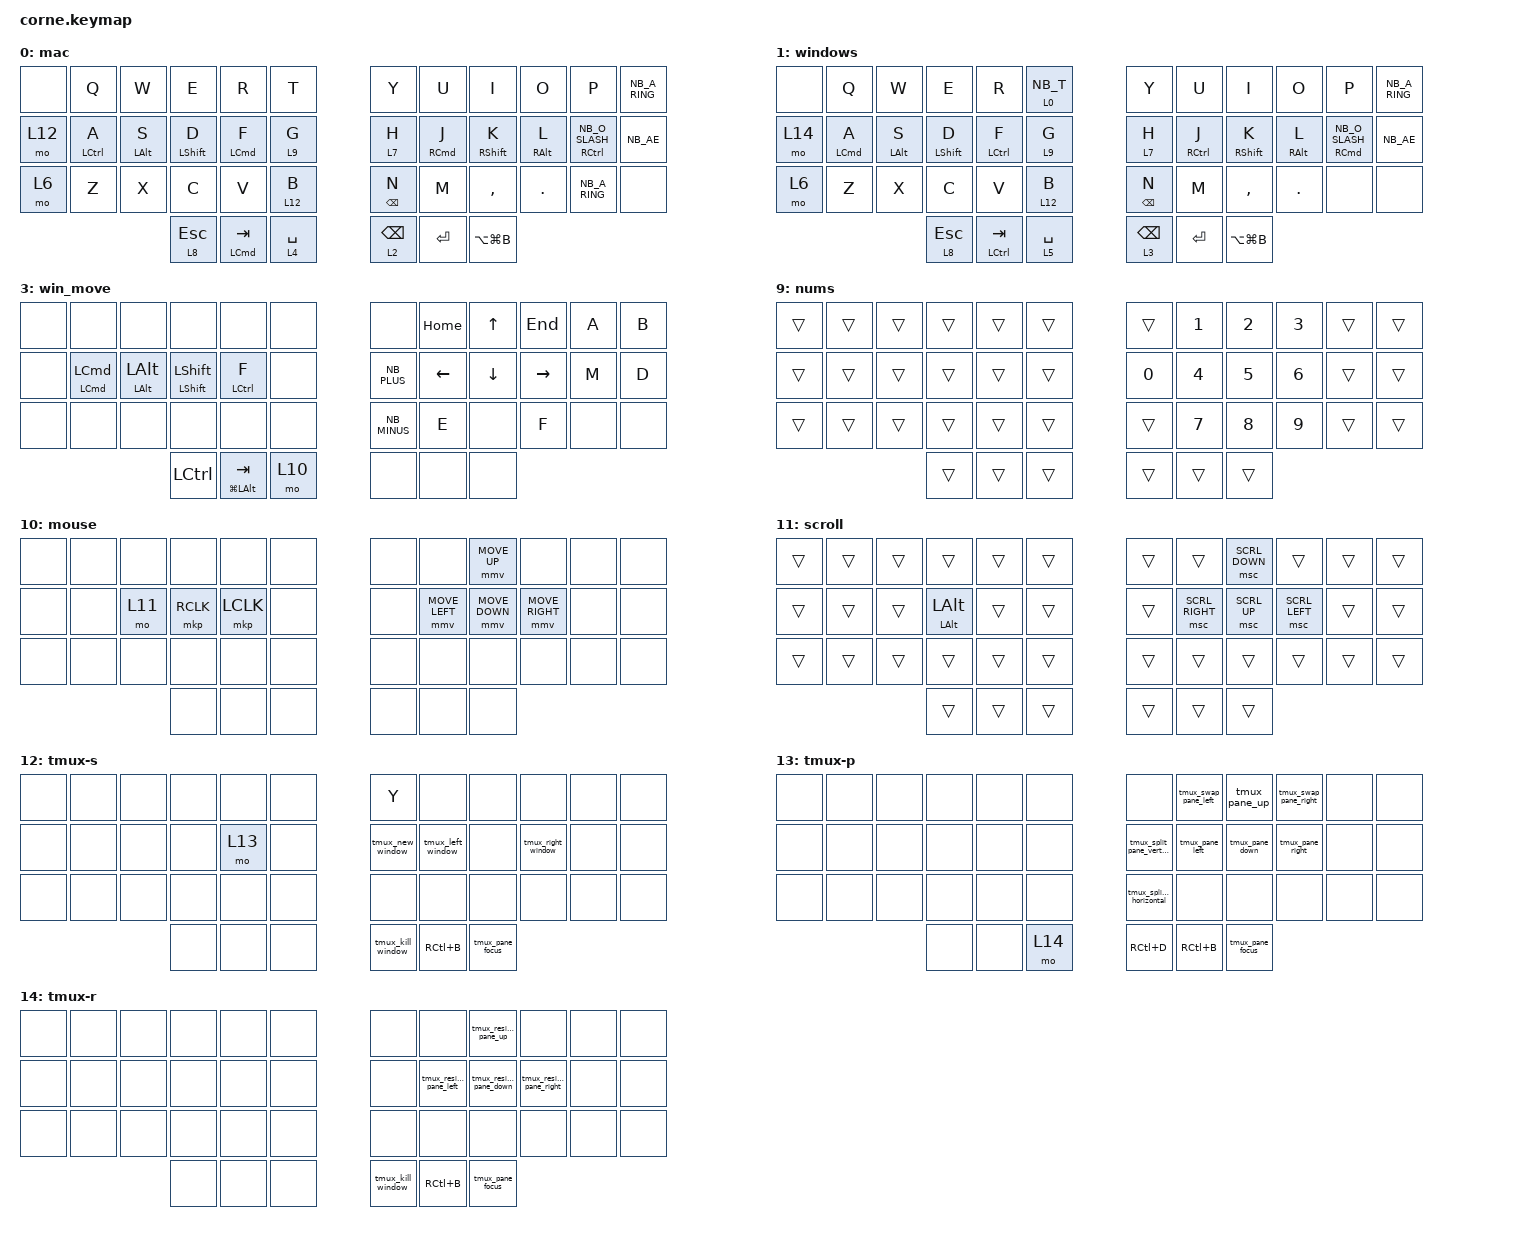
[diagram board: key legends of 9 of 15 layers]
/*
 * Copyright (c) 2020 The ZMK Contributors
 *
 * SPDX-License-Identifier: MIT
 */

#include "keys_nb.h"
#include <behaviors.dtsi>
#include <dt-bindings/zmk/bt.h>
#include <dt-bindings/zmk/keys.h>
#include <dt-bindings/zmk/pointing.h>

#define ZMK_POINTING_DEFAULT_MOVE_VAL 900

/ {
    behaviors {
        mt: mod_tap {
            compatible = "zmk,behavior-hold-tap";
            #binding-cells = <2>;
            flavor = "tap-preferred";
            tapping-term-ms = <180>;
            require-prior-idle-ms = <150>;
            bindings = <&kp>, <&kp>;

            #binding-cells = <2>;
            hold-trigger-on-release;
        };

        os_mac: os_mac {
            compatible = "zmk,behavior-macro";
            label = "OS_MAC";
            #binding-cells = <0>;

            // Select BLE profile 0 and set base layer to Mac (layer 0)

            bindings = <&bt BT_SEL 0 &to 0>;
        };

        os_win: os_win {
            compatible = "zmk,behavior-macro";
            label = "OS_WIN";
            #binding-cells = <0>;

            // Select BLE profile 1 and set base layer to Windows (layer 1)

            bindings = <&bt BT_SEL 1 &to 1>;
        };
    };

    macros {
        tmux_new_window: tmux_new_window {
            compatible = "zmk,behavior-macro";
            #binding-cells = <0>;
            bindings = <&kp RC(B) &kp C>;
            label = "TMUX_NEW_WINDOW";
        };

        tmux_window_1: tmux_window_1 {
            compatible = "zmk,behavior-macro";
            #binding-cells = <0>;
            bindings = <&kp RC(B) &kp N0>;
            label = "TMUX_WINDOW_1";
        };

        tmux_window_2: tmux_window_2 {
            compatible = "zmk,behavior-macro";
            #binding-cells = <0>;
            bindings = <&kp RC(B) &kp N1>;
            label = "TMUX_WINDOW_2";
        };

        tmux_window_3: tmux_window_3 {
            compatible = "zmk,behavior-macro";
            #binding-cells = <0>;
            bindings = <&kp RC(B) &kp NUMBER_2>;
            label = "TMUX_WINDOW_3";
        };

        tmux_window_4: tmux_window_4 {
            compatible = "zmk,behavior-macro";
            #binding-cells = <0>;
            bindings = <&kp RC(B) &kp NUMBER_3>;
            label = "TMUX_WINDOW_4";
        };

        tmux_kill_window: tmux_kill_window {
            compatible = "zmk,behavior-macro";
            #binding-cells = <0>;
            bindings = <&kp RC(B) &kp NB_AMPERSAND>;
            label = "TMUX_KILL_WINDOW";
        };

        tmux_right_window: tmux_right_arrow {
            compatible = "zmk,behavior-macro";
            #binding-cells = <0>;
            bindings = <&kp RC(B) &kp N>;
            label = "TMUX_RIGHT_ARROW";
        };

        tmux_left_window: tmux_left_arrow {
            compatible = "zmk,behavior-macro";
            #binding-cells = <0>;
            bindings = <&kp RC(B) &kp P>;
            label = "TMUX_LEFT_ARROW";
        };

        tmux_split_pane_horizontal: tmux_split_pane_up {
            compatible = "zmk,behavior-macro";
            #binding-cells = <0>;
            bindings = <&kp RC(B) &kp NB_DOUBLE_QUOTES>;
            label = "TMUX_SPLIT_PANE_UP";
        };

        tmux_split_pane_vertical: tmux_split_pane_down {
            compatible = "zmk,behavior-macro";
            #binding-cells = <0>;
            bindings = <&kp RC(B) &kp NB_PERCENT>;
            label = "TMUX_SPLIT_PANE_DOWN";
        };

        tmux_pane_up: tmux_pane_up {
            compatible = "zmk,behavior-macro";
            #binding-cells = <0>;
            bindings = <&kp RC(B) &kp UP_ARROW>;
            label = "TMUX_PANE_UP";
        };

        tmux_pane_down: tmux_pane_down {
            compatible = "zmk,behavior-macro";
            #binding-cells = <0>;
            bindings = <&kp RC(B) &kp DOWN_ARROW>;
            label = "TMUX_PANE_DOWN";
        };

        tmux_pane_left: tmux_pane_left {
            compatible = "zmk,behavior-macro";
            #binding-cells = <0>;
            bindings = <&kp RC(B) &kp LEFT_ARROW>;
            label = "TMUX_PANE_LEFT";
        };

        tmux_pane_right: tmux_pane_right {
            compatible = "zmk,behavior-macro";
            #binding-cells = <0>;
            bindings = <&kp RC(B) &kp RIGHT_ARROW>;
            label = "TMUX_PANE_RIGHT";
        };

        tmux_swap_pane_left: tmux_swap_pane_left {
            compatible = "zmk,behavior-macro";
            #binding-cells = <0>;
            bindings = <&kp RC(B) &kp LA(LS(N8))>;
            label = "TMUX_SWAP_PANE_LEFT";
        };

        tmux_swap_pane_right: tmux_swap_pane_right {
            compatible = "zmk,behavior-macro";
            #binding-cells = <0>;
            bindings = <&kp RC(B) &kp LA(LS(N9))>;
            label = "TMUX_SWAP_PANE_RIGHT";
        };

        tmux_pane_focus: tmux_pane_focus {
            compatible = "zmk,behavior-macro";
            #binding-cells = <0>;
            bindings = <&kp RC(B)>, <&macro_wait_time 50>, <&kp Z>;

            label = "TMUX_PANE_FOCUS";
        };

        tmux_resize_pane_up: tmux_resize_pane_up {
            compatible = "zmk,behavior-macro";
            #binding-cells = <0>;
            bindings =
                <&kp RC(B)>,
                <&macro_wait_time 50>,
                <&mt RC(PAGE_UP) RC(PAGE_UP)>;

            label = "TMUX_RESIZE_PANE_UP";
        };

        tmux_resize_pane_down: tmux_resize_pane_down {
            compatible = "zmk,behavior-macro";
            #binding-cells = <0>;
            bindings =
                <&kp RC(B)>,
                <&macro_wait_time 50>,
                <&mt RC(PAGE_DOWN) RC(PAGE_DOWN)>;

            label = "TMUX_RESIZE_PANE_DOWN";
        };

        tmux_resize_pane_left: tmux_resize_pane_left {
            compatible = "zmk,behavior-macro";
            #binding-cells = <0>;
            bindings =
                <&kp RC(B)>,
                <&macro_wait_time 50>,
                <&mt RC(C_MENU_LEFT) RC(C_MENU_LEFT)>;

            label = "TMUX_RESIZE_PANE_LEFT";
        };

        tmux_resize_pane_right: tmux_resize_pane_right {
            compatible = "zmk,behavior-macro";
            #binding-cells = <0>;
            bindings =
                <&kp RC(B)>,
                <&macro_wait_time 50>,
                <&mt RC(C_MENU_RIGHT) RC(C_MENU_RIGHT)>;

            label = "TMUX_RESIZE_PANE_RIGHT";
        };

        editor_focus_left: editor_focus_left {
            compatible = "zmk,behavior-macro";
            #binding-cells = <0>;
            bindings = <&kp RG(K)>, <&macro_wait_time 10>, <&kp RG(LEFT_ARROW)>;

            label = "EDITOR_FOCUS_LEFT";
        };

        editor_focus_right: editor_focus_right {
            compatible = "zmk,behavior-macro";
            #binding-cells = <0>;
            bindings =
                <&kp RG(K)>,
                <&macro_wait_time 10>,
                <&kp RG(RIGHT_ARROW)>;

            label = "EDITOR_FOCUS_RIGHT";
        };

        os_mac2: os_mac2 {
            compatible = "zmk,behavior-macro";
            #binding-cells = <0>;
            bindings = <&bt BT_SEL 3 &to 0>;
            label = "OS_MAC2";
        };
    };

    keymap {
        compatible = "zmk,keymap";

        Mac_Base {
            display-name = "mac";
            bindings = <
&none   &kp Q               &kp W           &kp E             &kp R                 &kp T          &kp Y            &kp U                &kp I              &kp O            &kp P                         &kp NB_A_RING
&mo 12  &mt LEFT_CONTROL A  &mt LEFT_ALT S  &mt LEFT_SHIFT D  &mt LEFT_COMMAND F    &lt 9 G        &lt 7 H          &mt RIGHT_COMMAND J  &mt RIGHT_SHIFT K  &mt RIGHT_ALT L  &mt RIGHT_CONTROL NB_O_SLASH  &kp NB_AE
&mo 6   &kp Z               &kp X           &kp C             &kp V                 &lt 12 B       &mt BACKSPACE N  &kp M                &kp COMMA          &kp DOT          &kp NB_A_RING                 &none
                                            &lt 8 ESC         &mt LEFT_COMMAND TAB  &lt 4 SPACE    &lt 2 BACKSPACE  &kp ENTER            &kp LA(LG(B))
            >;
        };

        Windows_Base {
            display-name = "windows";
            bindings = <
&none   &kp Q               &kp W           &kp E             &kp R                 &lt 0 NB_T     &kp Y            &kp U                &kp I              &kp O            &kp P                         &kp NB_A_RING
&mo 14  &mt LEFT_COMMAND A  &mt LEFT_ALT S  &mt LEFT_SHIFT D  &mt LEFT_CONTROL F    &lt 9 G        &lt 7 H          &mt RIGHT_CONTROL J  &mt RIGHT_SHIFT K  &mt RIGHT_ALT L  &mt RIGHT_COMMAND NB_O_SLASH  &kp NB_AE
&mo 6   &kp Z               &kp X           &kp C             &kp V                 &lt 12 B       &mt BACKSPACE N  &kp M                &kp COMMA          &kp DOT          &none                         &none
                                            &lt 8 ESC         &mt LEFT_CONTROL TAB  &lt 5 SPACE    &lt 3 BACKSPACE  &kp ENTER            &kp LA(LG(B))
            >;
        };

        Mac_Movement {
            display-name = "mac_move";
            bindings = <
&none  &none                          &none                  &none                      &none                          &none     &none         &kp HOME  &kp UP    &kp END    &kp A  &kp B
&none  &mt LEFT_CONTROL LEFT_CONTROL  &mt LEFT_ALT LEFT_ALT  &mt LEFT_SHIFT LEFT_SHIFT  &mt LEFT_COMMAND LEFT_COMMAND  &none     &kp NB_PLUS   &kp LEFT  &kp DOWN  &kp RIGHT  &kp M  &kp D
&none  &none                          &none                  &none                      &none                          &none     &kp NB_MINUS  &kp E     &none     &kp F      &none  &none
                                                             &kp LEFT_CONTROL           &kp LS(LC(LG(LEFT_ALT)))       &mo 10    &none         &none     &none
            >;
        };

        Windows_Movement {
            display-name = "win_move";
            bindings = <
&none  &none                          &none                  &none                      &none                 &none     &none         &kp HOME  &kp UP    &kp END    &kp A  &kp B
&none  &mt LEFT_COMMAND LEFT_COMMAND  &mt LEFT_ALT LEFT_ALT  &mt LEFT_SHIFT LEFT_SHIFT  &mt LEFT_CONTROL F    &none     &kp NB_PLUS   &kp LEFT  &kp DOWN  &kp RIGHT  &kp M  &kp D
&none  &none                          &none                  &none                      &none                 &none     &kp NB_MINUS  &kp E     &none     &kp F      &none  &none
                                                             &kp LEFT_CONTROL           &mt LG(LEFT_ALT) TAB  &mo 10    &none         &none     &none
            >;
        };

        Mac_Symbols {
            display-name = "symbols";
            bindings = <
&none  &kp LS(NUMBER_4)                       &kp NB_LESS_THAN         &kp NB_GREATER_THAN  &kp NB_UNDERSCORE  &kp RA(N7)         &kp NB_AMPERSAND    &kp LA(LS(NB_N8))        &kp LS(LA(N9))            &kp NB_EQUAL  &kp RA(SINGLE_QUOTE)  &none
&none  &kp NB_DOUBLE_QUOTES                   &kp LA(NB_SINGLE_QUOTE)  &kp NB_SEMICOLON     &kp NB_COLON       &kp NB_SLASH       &kp NB_QUESTION     &kp NB_LEFT_PARENTHESIS  &kp NB_RIGHT_PARENTHESIS  &kp NB_PLUS   &kp NB_SINGLE_QUOTE   &none
&none  &mt LA(LC(LG(LEFT_SHIFT))) LEFT_SHIFT  &none                    &none                &kp NB_HASH        &kp NB_ASTERISK    &kp NB_EXCLAMATION  &kp NB_LEFT_BRACKET      &kp NB_RIGHT_BRACKET      &kp NB_MINUS  &none                 &none
                                                                       &none                &none              &none              &mo 10              &kp NB_PERCENT           &none
            >;
        };

        Windows_Symbols {
            display-name = "symbols";
            bindings = <
&none  &kp NB_DOLLAR                          &kp NB_LESS_THAN  &kp NB_GREATER_THAN  &kp NB_UNDERSCORE  &kp NB_PIPE        &kp NB_AMPERSAND    &kp NB_LEFT_BRACE        &kp NB_RIGHT_BRACE        &kp NB_EQUAL  &kp RA(SINGLE_QUOTE)  &none
&none  &kp NB_DOUBLE_QUOTES                   &kp NB_SQT        &kp NB_SEMICOLON     &kp NB_COLON       &kp NB_SLASH       &kp NB_QUESTION     &kp NB_LEFT_PARENTHESIS  &kp NB_RIGHT_PARENTHESIS  &kp NB_PLUS   &kp NB_AT_SIGN        &none
&none  &mt LA(LC(LG(LEFT_SHIFT))) LEFT_SHIFT  &kp NB_BACKSLASH  &none                &kp NB_HASH        &kp NB_ASTERISK    &kp NB_EXCLAMATION  &kp NB_LEFT_BRACKET      &kp NB_RIGHT_BRACKET      &kp NB_MINUS  &none                 &none
                                                                &none                &none              &none              &mo 10              &kp NB_PERCENT           &none
            >;
        };

        Misc {
            display-name = "misc";
            bindings = <
&bt BT_CLR_ALL  &none  &bt BT_CLR  &os_mac2              &os_mac               &os_win              &kp C_PLAY_PAUSE  &kp C_VOLUME_DOWN  &kp C_VOLUME_UP  &kp C_PREVIOUS  &kp C_NEXT  &none
&none           &none  &none       &kp LS(LG(NUMBER_5))  &kp LS(LG(NUMBER_4))  &kp LS(LA(S))        &none             &none              &none            &none           &none       &none
&none           &none  &none       &none                 &none                 &kp LS(LA(LC(S)))    &none             &none              &none            &none           &none       &none
                                   &none                 &none                 &none                &none             &none              &none
            >;
        };

        Apps {
            display-name = "apps";
            bindings = <
&kp LS(LA(LC(LG(NB_N1))))  &kp LC(NB_N8)  &kp LC(NB_N1)   &kp LC(NB_N2)  &kp LC(NB_N3)  &kp LC(NB_N0)        &none  &none  &none  &none  &none  &none
&none                      &kp LC(NB_N9)  &kp LS(LC(N7))  &kp LC(N7)     &kp LC(NB_N6)  &kp LC(LS(NB_N6))    &none  &none  &none  &none  &none  &none
&none                      &none          &none           &none          &none          &kp LG(Q)            &none  &none  &none  &none  &none  &none
                                                          &none          &none          &none                &none  &none  &none
            >;
        };

        IDE {
            display-name = "ide";
            bindings = <
&none  &none  &none               &none  &none                &none    &kp LG(W)      &kp RG(N1)                 &kp RG(N2)  &kp RG(N3)                 &none  &none
&none  &none  &editor_focus_left  &none  &editor_focus_right  &none    &kp LG(P)      &kp LS(LA(LC(LG(NB_N5))))  &none       &kp LS(LA(LC(LG(NB_N6))))  &none  &none
&none  &none  &none               &none  &none                &none    &none          &none                      &none       &none                      &none  &none
                                  &none  &none                &none    &kp RG(RS(E))  &kp RC(NB_PLUS)            &none
            >;
        };

        Nums {
            display-name = "nums";
            bindings = <
&trans  &trans  &trans  &trans  &trans  &trans    &trans  &kp N1  &kp N2  &kp N3  &trans  &trans
&trans  &trans  &trans  &trans  &trans  &trans    &kp N0  &kp N4  &kp N5  &kp N6  &trans  &trans
&trans  &trans  &trans  &trans  &trans  &trans    &trans  &kp N7  &kp N8  &kp N9  &trans  &trans
                        &trans  &trans  &trans    &trans  &trans  &trans
            >;
        };

        mouse {
            display-name = "mouse";
            bindings = <
&none  &none  &none   &none      &none      &none    &none  &none           &mmv MOVE_UP    &none            &none  &none
&none  &none  &mo 11  &mkp RCLK  &mkp LCLK  &none    &none  &mmv MOVE_LEFT  &mmv MOVE_DOWN  &mmv MOVE_RIGHT  &none  &none
&none  &none  &none   &none      &none      &none    &none  &none           &none           &none            &none  &none
                      &none      &none      &none    &none  &none           &none
            >;
        };

        Scroll {
            display-name = "scroll";
            bindings = <
&trans  &trans  &trans  &trans                 &trans  &trans    &trans  &trans           &msc SCRL_DOWN  &trans          &trans  &trans
&trans  &trans  &trans  &mt LEFT_ALT LEFT_ALT  &trans  &trans    &trans  &msc SCRL_RIGHT  &msc SCRL_UP    &msc SCRL_LEFT  &trans  &trans
&trans  &trans  &trans  &trans                 &trans  &trans    &trans  &trans           &trans          &trans          &trans  &trans
                        &trans                 &trans  &trans    &trans  &trans           &trans
            >;
        };

        tmux-s {
            display-name = "tmux-s";
            bindings = <
&none  &none  &none  &none  &none   &none    &kp Y              &none              &none             &none               &none  &none
&none  &none  &none  &none  &mo 13  &none    &tmux_new_window   &tmux_left_window  &none             &tmux_right_window  &none  &none
&none  &none  &none  &none  &none   &none    &none              &none              &none             &none               &none  &none
                     &none  &none   &none    &tmux_kill_window  &kp RC(B)          &tmux_pane_focus
            >;
        };

        tmux-p {
            display-name = "tmux-p";
            bindings = <
&none  &none  &none  &none  &none  &none     &none                        &tmux_swap_pane_left  &tmux_pane_up     &tmux_swap_pane_right  &none  &none
&none  &none  &none  &none  &none  &none     &tmux_split_pane_vertical    &tmux_pane_left       &tmux_pane_down   &tmux_pane_right       &none  &none
&none  &none  &none  &none  &none  &none     &tmux_split_pane_horizontal  &none                 &none             &none                  &none  &none
                     &none  &none  &mo 14    &kp RC(D)                    &kp RC(B)             &tmux_pane_focus
            >;
        };

        tmux-r {
            display-name = "tmux-r";
            bindings = <
&none  &none  &none  &none  &none  &none    &none              &none                   &tmux_resize_pane_up    &none                    &none  &none
&none  &none  &none  &none  &none  &none    &none              &tmux_resize_pane_left  &tmux_resize_pane_down  &tmux_resize_pane_right  &none  &none
&none  &none  &none  &none  &none  &none    &none              &none                   &none                   &none                    &none  &none
                     &none  &none  &none    &tmux_kill_window  &kp RC(B)               &tmux_pane_focus
            >;
        };
    };
};
